# rCSL_intc_001 register map
Vendor: Texas Instruments
Peripheral module from a debugger description file (folder c674x).
Registers are 32-bit, read-write, reset 0x0 unless marked. A register's access mark holds for its fields unless they carry their own. Offsets are as the file gives them; lines under a group give offsets from that group; [hi:lo] are bit positions; {n}, {i} and the like mark numbered series; 'fields as' and 'values as' point back to an identical list; <NAME> marks a mode.

## AINTC — This module acts as interface between ARM9 and system interrupts.
0x00 REV ro reset 0x4E820100 — Read only ID register for AINTC.
  [31:0] REVID — Revision ID of AINTC. This is read only.
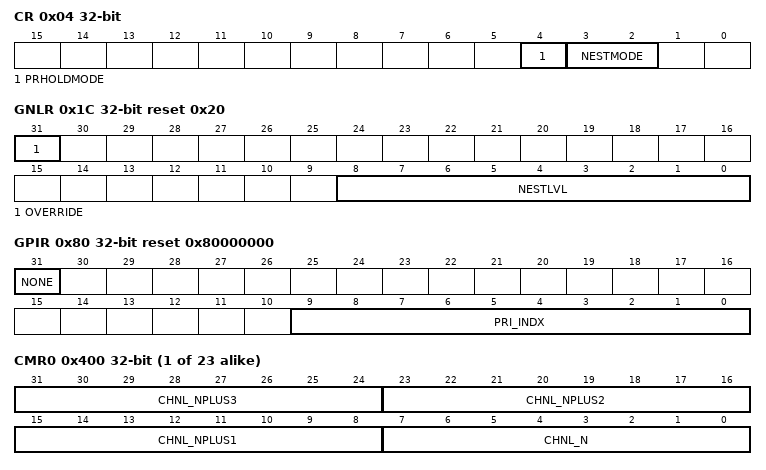
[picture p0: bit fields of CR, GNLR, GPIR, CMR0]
0x04 CR access not given — The Control Register holds global control parameters.
  [4] PRHOLDMODE rw — Enables priority holding mode.
    0=NO_PRHOLD (no priority holding, prioritized MMRs will continually update.); 1=PRHOLD (priority holding enabled, Prioritized Index and Vector Address MMRs will hold their value after the first is read and release the hold after either is written or Host Interrupt is set or cleared as described in functional section.)
  [3:2] NESTMODE rw — The nesting mode.
    0=NONEST (no nesting); 1=INDIVIDUAL (automatic individual nesting (per host interrupt)); 2=GLOBAL (automatic global nesting (over all host interrupts)); 3=MANUAL (manual nesting)
0x10 GER access not given — The Global Enable Register enables all the host interrupts. Individual host interrupts are still enabled or disabled from their individual enables and are not overridden by the global enable.
  [0] ENABLE rw — The current global enable value when read. Writes set the global enable
0x1C GNLR access not given reset 0x20 — The Global Nesting Level Register allows the checking and setting of the global nesting level across all host interrupts when automatic global nesting mode is set. The nesting level is the channel (and all of lower priority) that are nested out because of a current interrupt.
  [31] OVERRIDE rw — Always read as 0. Writes of 1 override the automatic nesting and set the NESTLVL to the written data.
  [8:0] NESTLVL rw — The current global nesting level (highest channel that is nested). Writes set the nesting level. In auto nesting mode this value is updated internally unless the auto_override bit is set.
0x20 SISR access not given — The System Interrupt Status Indexed Set Register allows setting the status of an interrupt. The interrupt to set is the INDEX value written. This sets the Raw Status Register bit of the given INDEX.
  [9:0] INDEX wo — Writes set the status of the interrupt given in the INDEX value. Reads return 0.
0x24 SICR access not given — This register allows clearing the status of an interrupt. The interrupt to clear is the INDEX value written. This clears the Raw Status Register bit of the given INDEX.
  [9:0] INDEX wo — Writes clear the status of the interrupt given in the INDEX value. Reads return 0.
0x28 EISR access not given — This register allows enabling an interrupt. The interrupt to enable is the INDEX value written. This sets the Enable Register bit of the given INDEX.
  [9:0] INDEX wo — Writes set the enable of the interrupt given in the INDEX value. Reads return 0.
0x2C EICR access not given — This register allows disabling an interrupt. The interrupt to disable is the INDEX value written. This clears the Enable Register bit of the given INDEX.
  [9:0] INDEX wo — Writes clear the enable of the interrupt given in the INDEX value. Reads return 0.
0x34 HIEISR access not given — This register allows enabling a host interrupt output. The host interrupt to enable is the INDEX value written. This enables the host interrupt output or triggers the output again if already enabled.
  [9:0] INDEX wo — Writes set the enable of the host interrupt given in the INDEX value. Reads return 0.
0x38 HIDISR access not given — This register allows disabling a host interrupt output. The host interrupt to disable is the INDEX value written. This disables the host interrupt output.
  [9:0] INDEX wo — Writes clear the enable of the host interrupt given in the INDEX value. Reads return 0.
0x50 VBR — This register holds the base address of the ISR vector addresses.
  [31:0] BASE — ISR Base Address.
0x54 VSR access not given — This register holds the sizes of the individual ISR routines in the vector table. This is only the sizes to space the calculated vector addresses for the initial ISR targets (the ISR targets could branch off to the full ISR routines).
  [7:0] SIZE rw — Size of ISR address spaces
0x58 VNR — This register holds the address of the ISR null address that handles no pending interrupts (if accidentally branched to when no interrupts are pending).
  [31:0] NULL — ISR Null address.
0x80 GPIR access not given reset 0x80000000 — This register shows the interrupt number of the highest priority interrupt pending across all the host interrupts.
  [31] NONE ro — No Interrupt is pending. Can be used by host to test for a negative value to see if no interrupts are pending.
  [9:0] PRI_INDX ro — The currently highest priority interrupt index pending across all the host interrupts.
0x84 GPVR ro — This register shows the interrupt vector address of the highest priority interrupt pending across all the host interrupts.
  [31:0] ADDR — The currently highest priority interrupts vector address across all the host interrupts.
0x200 SRSR1 wo — This register shows the pending enabled status of the system interrupts 0 to 31. Software can write to the Status Set Registers to set a system interrupt without a hardware trigger. There is one bit per system interrupt.
  [31:0] RAW_STATUS — System interrupt raw status and setting. Reads return the raw status. Write a 1 in a bit position to set the status of the system interrupt. Writing a 0 has no effect.
0x204 SRSR2 wo — This register shows the pending enabled status of the system interrupts 32 to 63. Software can write to the Status Set Registers to set a system interrupt without a hardware trigger. There is one bit per system interrupt.
  fields as SRSR1
0x208 SRSR3 access not given — This register shows the pending enabled status of the system interrupts 64 to 90. Software can write to the Status Set Registers to set a system interrupt without a hardware trigger. There is one bit per system interrupt.
  [26:0] RAW_STATUS wo — System interrupt raw status and setting. Reads return the raw status. Write a 1 in a bit position to set the status of the system interrupt. Writing a 0 has no effect.
0x280 SECR1 wo — This register shows the pending enabled status of the system interrupts 0 to 31. Software can write to the Status Clear Registers to clear a system interrupt after it has been serviced. If a system interrupt status is not cleared then another host interrupt may not be triggered or another host interrupt may be triggered incorrectly. There is one bit per system interrupt.
  [31:0] ENBL_STATUS — System interrupt enabled status and clearing. Reads return the enabled status (before enabling with the Enable Registers). Write a 1 in a bit position to clear the status of the system interrupt. Writing a 0 has no effect.
0x284 SECR2 wo — This register shows the pending enabled status of the system interrupts 32 to 63. Software can write to the Status Clear Registers to clear a system interrupt after it has been serviced. If a system interrupt status is not cleared then another host interrupt may not be triggered or another host interrupt may be triggered incorrectly. There is one bit per system interrupt.
  fields as SECR1
0x288 SECR3 access not given — This register shows the pending enabled status of the system interrupts 64 to 90. Software can write to the Status Clear Registers to clear a system interrupt after it has been serviced. If a system interrupt status is not cleared then another host interrupt may not be triggered or another host interrupt may be triggered incorrectly. There is one bit per system interrupt.
  [26:0] ENBL_STATUS wo — System interrupt enabled status and clearing. Reads return the enabled status (before enabling with the Enable Registers). Write a 1 in a bit position to clear the status of the system interrupt. Writing a 0 has no effect.
0x300 ESR1 wo — This register enables system interrupts 0 to 31 to trigger outputs. System interrupts that are not enabled do not interrupt the host. There is a bit per system interrupt.
  [31:0] ENABLE — System interrupt enables. Read returns the enable value (0 = disabled, 1 = enabled). Write a 1 in a bit position to set that enable. Writing a 0 has no effect.
0x304 ESR2 wo — This register enables system interrupts 32 to 63 to trigger outputs. System interrupts that are not enabled do not interrupt the host. There is a bit per system interrupt.
  fields as ESR1
0x308 ESR3 access not given — This register enables system interrupts 63 to 90 to trigger outputs. System interrupts that are not enabled do not interrupt the host. There is a bit per system interrupt.
  [26:0] ENABLE wo — System interrupt enables. Read returns the enable value (0 = disabled, 1 = enabled). Write a 1 in a bit position to set that enable. Writing a 0 has no effect.
0x380 ECR1 wo — This register disables system interrupts 0 to 31 to map to channels. System interrupts that are not enabled do not interrupt the host. There is a bit per system interrupt.
  [31:0] DISABLE — System interrupt disable. Read returns the enable value (0 = disabled, 1 = enabled). Write a 1 in a bit position to clear that enable. Writing a 0 has no effect.
0x384 ECR2 wo — This register disables system interrupts 32 to 63 to map to channels. System interrupts that are not enabled do not interrupt the host. There is a bit per system interrupt.
  fields as ECR1
0x388 ECR3 access not given — This register disables system interrupts 64 to 90 to map to channels. System interrupts that are not enabled do not interrupt the host. There is a bit per system interrupt.
  [26:0] DISABLE wo — System interrupt disable. Read returns the enable value (0 = disabled, 1 = enabled). Write a 1 in a bit position to clear that enable. Writing a 0 has no effect.
{0x400+4i} CMR{i} (i=0..22) — These registers define the channel for each system interrupt. There is one register per 4 system interrupts.
  [31:24] CHNL_NPLUS3 — Sets the host interrupt for channel N + 3
  [23:16] CHNL_NPLUS2 — Sets the host interrupt for channel N + 2
  [15:8] CHNL_NPLUS1 — Sets the host interrupt for channel N + 1
  [7:0] CHNL_N — Sets the channel for the system interrupt N. (N ranges from 0 to 90)
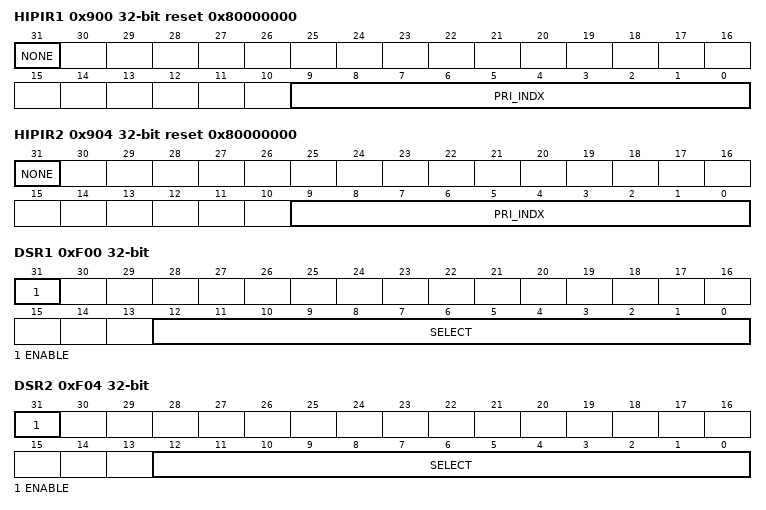
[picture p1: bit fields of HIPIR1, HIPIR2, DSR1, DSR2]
0x900 HIPIR1 access not given reset 0x80000000 — This register shows the highest priority current pending interrupt for the FIQ interrupt.
  [31] NONE ro — No Interrupt is pending.
  [9:0] PRI_INDX ro — Interrupt number of the highest priority pending interrupt for FIQ host interrupt.
0x904 HIPIR2 access not given reset 0x80000000 — This register shows the highest priority current pending interrupt for the IRQ interrupt.
  [31] NONE ro — No Interrupt is pending.
  [9:0] PRI_INDX ro — Interrupt number of the highest priority pending interrupt for IRQ host interrupt.
0xD80 SITR1 — This register defines the type of the system interrupts 0 to 31. There is a type for each system interrupt.
  [31:0] TYPE — System interrupt type.
    0=LEVEL (Level or pulse interrupts); 1=EDGE (Edge interrupt (required edge detect))
0xD84 SITR2 — This register defines the type of the system interrupts 32 to 63. There is a type for each system interrupt.
  fields as SITR1
0xD88 SITR3 access not given — This register defines the type of the system interrupts 64 to 90. There is a type for each system interrupt.
  [26:0] TYPE rw — System interrupt type.
    values as SITR1.TYPE
0xF00 DSR1 access not given — This register selects which interrupt source generates the debug interrupt output.
  [31] ENABLE rw — Debug interrupt enable.
    0=DISABLE (Debug interrupt-1 disabled); 1=ENABLE (Debug interrupt-1 enabled)
  [12:0] SELECT rw — Debug interrupt source select.
0xF04 DSR2 access not given — This register selects which interrupt source generates the debug interrupt output.
  [31] ENABLE rw — Debug interrupt enable.
    0=DISABLE (Debug interrupt-2 disabled); 1=ENABLE (Debug interrupt-2 enabled)
  [12:0] SELECT rw — Debug interrupt source select.
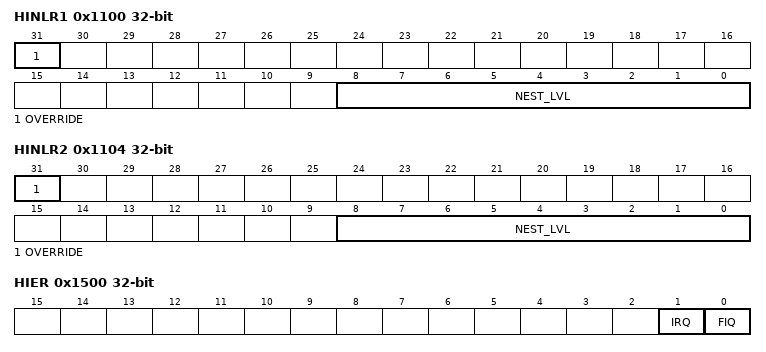
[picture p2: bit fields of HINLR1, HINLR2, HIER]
0x1100 HINLR1 access not given — This register displays and controls the nesting level for FIQ host interrupt. The nesting level controls which channel and lower priority channels are nested.
  [31] OVERRIDE wo — Reads return 0. Writes of a 1 override the auto updating of the NEST_LVL and use the write data.
  [8:0] NEST_LVL rw — Reads return the current nesting level for the FIQ host interrupt. Writes set the nesting level for the FIQ host interrupt. In auto mode the value is updated internally unless the OVERRIDE is set and then the write data is used.
0x1104 HINLR2 access not given — This register displays and controls the nesting level for IRQ host interrupt. The nesting level controls which channel and lower priority channels are nested.
  [31] OVERRIDE wo — Reads return 0. Writes of a 1 override the auto updating of the NEST_LVL and use the write data.
  [8:0] NEST_LVL rw — Reads return the current nesting level for the IRQ host interrupt. Writes set the nesting level for the IRQ host interrupt. In auto mode the value is updated internally unless the OVERRIDE is set and then the write data is used.
0x1500 HIER access not given — This register enables or disables individual host interrupts(FIQ and IRQ). These work separately from the global enables. There is one bit per host interrupt. These bits are updated when writing to the Host Interrupt Enable Index Set and Host Interrupt Enable Index Clear registers.
  [1] IRQ rw — Enable of IRQ
    0=? (disabled); 1=? (enabled)
  [0] FIQ rw — Enable of FIQ
    0=? (disabled); 1=? (enabled)
0x1600 HIPVR1 ro — This register shows the interrupt vector address of the highest priority interrupt pending for FIQ host interrupt.
  [31:0] ADDR — The currently highest priority interrupt vector address across for the FIQ host interrupt.
0x1604 HIPVR2 ro — This register shows the interrupt vector address of the highest priority interrupt pending for IRQ host interrupt.
  [31:0] ADDR — The currently highest priority interrupt vector address across for the IRQ host interrupt.
